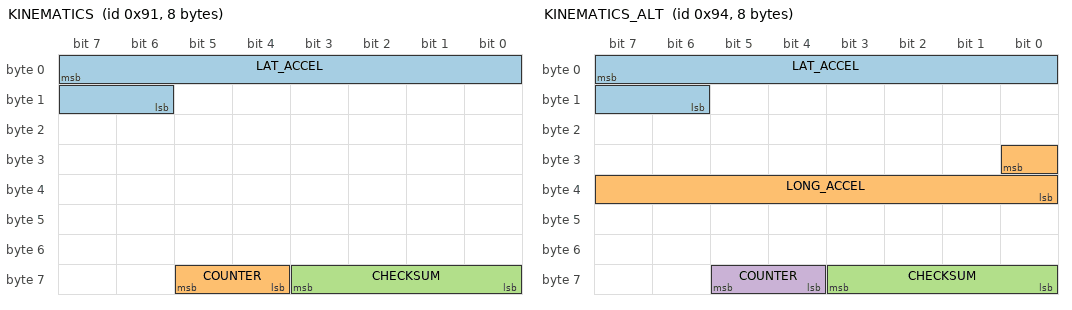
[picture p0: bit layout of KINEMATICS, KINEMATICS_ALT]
BO_ 145 KINEMATICS: 8 XXX
 SG_ LAT_ACCEL : 7|10@0+ (0.02,-512) [-20|20] "m/s2" EON
 SG_ COUNTER : 61|2@0+ (1,0) [0|3] "" EON
 SG_ CHECKSUM : 59|4@0+ (1,0) [0|3] "" EON

BO_ 148 KINEMATICS_ALT: 8 XXX
 SG_ LAT_ACCEL : 7|10@0+ (0.02,-512) [-20|20] "m/s2" EON
 SG_ LONG_ACCEL : 24|9@0- (-0.02,0) [-20|20] "m/s2" EON
 SG_ CHECKSUM : 59|4@0+ (1,0) [0|3] "" EON
 SG_ COUNTER : 61|2@0+ (1,0) [0|3] "" EON

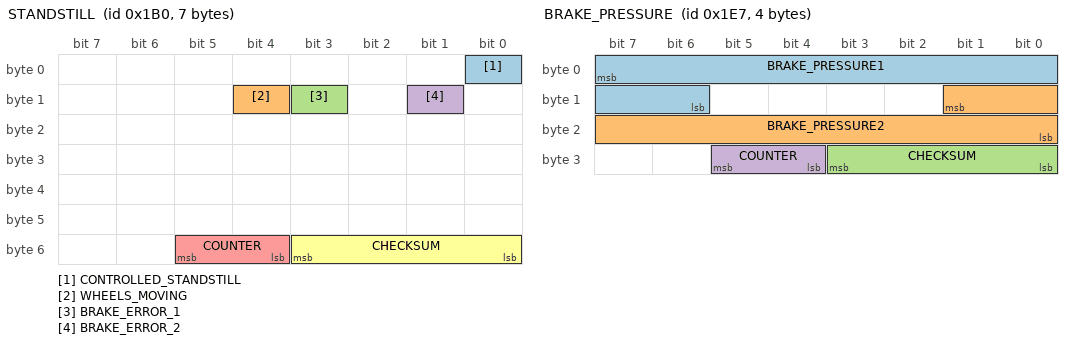
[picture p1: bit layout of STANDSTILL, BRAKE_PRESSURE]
BO_ 432 STANDSTILL: 7 VSA
 SG_ CONTROLLED_STANDSTILL : 0|1@0+ (1,0) [0|1] "" EON
 SG_ WHEELS_MOVING : 12|1@0+ (1,0) [0|1] "" EON
 SG_ BRAKE_ERROR_1 : 11|1@0+ (1,0) [0|1] "" EON
 SG_ BRAKE_ERROR_2 : 9|1@0+ (1,0) [0|1] "" EON
 SG_ COUNTER : 53|2@0+ (1,0) [0|3] "" EON
 SG_ CHECKSUM : 51|4@0+ (1,0) [0|3] "" EON

BO_ 487 BRAKE_PRESSURE: 4 VSA
 SG_ BRAKE_PRESSURE1 : 7|10@0+ (0.015625,-103) [0|1000] "" EON
 SG_ BRAKE_PRESSURE2 : 9|10@0+ (0.015625,-103) [0|1000] "" EON
 SG_ CHECKSUM : 27|4@0+ (1,0) [0|15] "" EON
 SG_ COUNTER : 29|2@0+ (1,0) [0|3] "" EON

BO_ 506 BRAKE_COMMAND: 8 ADAS
 SG_ COMPUTER_BRAKE : 7|10@0+ (1,0) [0|1] "" EBCM
 SG_ SET_ME_X00 : 13|5@0+ (1,0) [0|1] "" EBCM
 SG_ BRAKE_PUMP_REQUEST : 8|1@0+ (1,0) [0|1] "" EBCM
 SG_ SET_ME_X00_2 : 23|3@0+ (1,0) [0|1] "" EBCM
 SG_ CRUISE_OVERRIDE : 20|1@0+ (1,0) [0|1] "" EBCM
 SG_ SET_ME_X00_3 : 19|1@0+ (1,0) [0|1] "" EBCM
 SG_ CRUISE_FAULT_CMD : 18|1@0+ (1,0) [0|1] "" EBCM
 SG_ CRUISE_CANCEL_CMD : 17|1@0+ (1,0) [0|1] "" EBCM
 SG_ COMPUTER_BRAKE_REQUEST : 16|1@0+ (1,0) [0|1] "" EBCM
 SG_ SET_ME_1 : 31|1@0+ (1,0) [0|1] "" EBCM
 SG_ AEB_REQ_1 : 29|1@0+ (1,0) [0|1] "" XXX
 SG_ AEB_REQ_2 : 26|3@0+ (1,0) [0|7] "" XXX
 SG_ BRAKE_LIGHTS : 39|1@0+ (1,0) [0|1] "" EBCM
 SG_ CRUISE_STATES : 38|7@0+ (1,0) [0|1] "" EBCM
 SG_ CHIME : 47|3@0+ (1,0) [0|7] "" EBCM
 SG_ SET_ME_X00_4 : 44|1@0+ (1,0) [0|1] "" EBCM
 SG_ FCW : 43|2@0+ (1,0) [0|3] "" EBCM
 SG_ AEB_STATUS : 41|2@0+ (1,0) [0|3] "" XXX
 SG_ SET_ME_X00_5 : 55|8@0+ (1,0) [0|0] "" EBCM
 SG_ COUNTER : 61|2@0+ (1,0) [0|3] "" EBCM
 SG_ CHECKSUM : 59|4@0+ (1,0) [0|15] "" EBCM

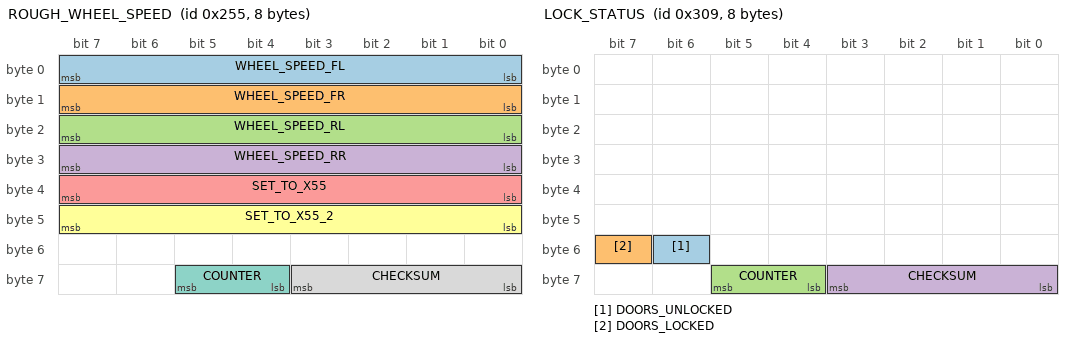
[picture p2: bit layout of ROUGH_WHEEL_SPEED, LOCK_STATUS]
BO_ 597 ROUGH_WHEEL_SPEED: 8 VSA
 SG_ WHEEL_SPEED_FL : 7|8@0+ (1,0) [0|255] "mph" EON
 SG_ WHEEL_SPEED_FR : 15|8@0+ (1,0) [0|255] "mph" EON
 SG_ WHEEL_SPEED_RL : 23|8@0+ (1,0) [0|255] "mph" EON
 SG_ WHEEL_SPEED_RR : 31|8@0+ (1,0) [0|255] "mph" EON
 SG_ SET_TO_X55 : 39|8@0+ (1,0) [0|255] "" EON
 SG_ SET_TO_X55_2 : 47|8@0+ (1,0) [0|255] "" EON
 SG_ COUNTER : 61|2@0+ (1,0) [0|3] "" EON
 SG_ CHECKSUM : 59|4@0+ (1,0) [0|15] "" EON

BO_ 777 LOCK_STATUS: 8 XXX
 SG_ DOORS_UNLOCKED : 54|1@0+ (1,0) [0|1] "" EON
 SG_ DOORS_LOCKED : 55|1@0+ (1,0) [0|1] "" EON
 SG_ COUNTER : 61|2@0+ (1,0) [0|3] "" EON
 SG_ CHECKSUM : 59|4@0+ (1,0) [0|3] "" EON

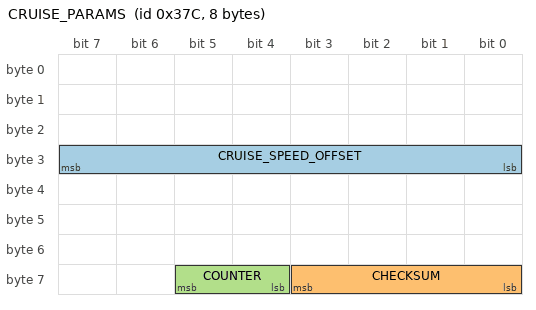
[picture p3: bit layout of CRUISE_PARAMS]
BO_ 892 CRUISE_PARAMS: 8 PCM
 SG_ CRUISE_SPEED_OFFSET : 31|8@0- (0.1,0) [-128|127] "kph" EON
 SG_ CHECKSUM : 59|4@0+ (1,0) [0|3] "" EON
 SG_ COUNTER : 61|2@0+ (1,0) [0|3] "" EON

CM_ SG_ 506 AEB_REQ_1 "set for duration of suspected AEB event";

VAL_ 506 FCW 3 "fcw" 2 "fcw" 1 "fcw" 0 "no_fcw";
VAL_ 506 CHIME 4 "double_chime" 3 "single_chime" 2 "continuous_chime" 1 "repeating_chime" 0 "no_chime";
VAL_ 506 AEB_STATUS 3 "aeb_prepare" 2 "aeb_ready" 1 "aeb_braking" 0 "no_aeb";
